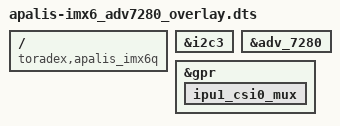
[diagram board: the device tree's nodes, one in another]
// SPDX-License-Identifier: GPL-2.0-or-later OR MIT
/*
 * Copyright 2020-2021 Toradex
 */

// Analogue Camera Adapter orderable at Toradex.

/dts-v1/;
/plugin/;

/ {
	compatible = "toradex,apalis_imx6q";
};

&i2c3 {
	status = "okay";
};

&adv_7280 {
	status = "okay";
};

&gpr {
	ipu1_csi0_mux {
		status = "okay";
	};
};
